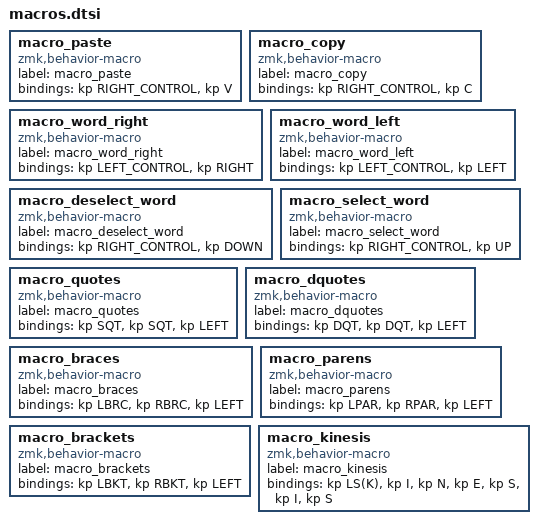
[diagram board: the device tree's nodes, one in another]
macro_paste: macro_paste{
compatible = "zmk,behavior-macro";
label = "macro_paste";
#binding-cells = <0>;
bindings = <&kp RIGHT_CONTROL>, <&kp V>;
};
macro_copy: macro_copy{
compatible = "zmk,behavior-macro";
label = "macro_copy";
#binding-cells = <0>;
bindings = <&kp RIGHT_CONTROL>, <&kp C>;
};
macro_word_right: macro_word_right{
compatible = "zmk,behavior-macro";
label = "macro_word_right";
#binding-cells = <0>;
bindings = <&kp LEFT_CONTROL>, <&kp RIGHT>;
};
macro_word_left: macro_word_left{
compatible = "zmk,behavior-macro";
label = "macro_word_left";
#binding-cells = <0>;
bindings = <&kp LEFT_CONTROL>, <&kp LEFT>;
};
macro_deselect_word: macro_deselect_word{
compatible = "zmk,behavior-macro";
label = "macro_deselect_word";
#binding-cells = <0>;
bindings = <&kp RIGHT_CONTROL>, <&kp DOWN>;
};
macro_select_word: macro_select_word{
compatible = "zmk,behavior-macro";
label = "macro_select_word";
#binding-cells = <0>;
bindings = <&kp RIGHT_CONTROL>, <&kp UP>;
};
macro_quotes: macro_quotes{
compatible = "zmk,behavior-macro";
label = "macro_quotes";
#binding-cells = <0>;
bindings = <&kp SQT>, <&kp SQT>, <&kp LEFT>;
};
macro_dquotes: macro_dquotes{
compatible = "zmk,behavior-macro";
label = "macro_dquotes";
#binding-cells = <0>;
bindings = <&kp DQT>, <&kp DQT>, <&kp LEFT>;
};
macro_braces: macro_braces{
compatible = "zmk,behavior-macro";
label = "macro_braces";
#binding-cells = <0>;
bindings = <&kp LBRC>, <&kp RBRC>, <&kp LEFT>;
};
macro_parens: macro_parens{
compatible = "zmk,behavior-macro";
label = "macro_parens";
#binding-cells = <0>;
bindings = <&kp LPAR>, <&kp RPAR>, <&kp LEFT>;
};
macro_brackets: macro_brackets{
compatible = "zmk,behavior-macro";
label = "macro_brackets";
#binding-cells = <0>;
bindings = <&kp LBKT>, <&kp RBKT>, <&kp LEFT>;
};
macro_kinesis: macro_kinesis{
compatible = "zmk,behavior-macro";
label = "macro_kinesis";
#binding-cells = <0>;
bindings = <&kp LS(K)>, <&kp I>, <&kp N>, <&kp E>, <&kp S>, <&kp I>, <&kp S>;
};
